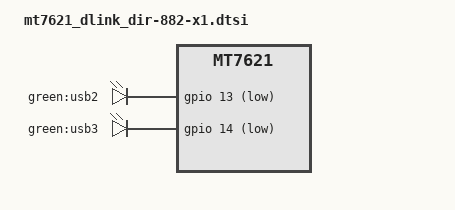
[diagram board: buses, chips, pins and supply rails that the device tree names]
// SPDX-License-Identifier: GPL-2.0-or-later OR MIT

&leds {
	usb2 {
		label = "green:usb2";
		gpios = <&gpio 13 GPIO_ACTIVE_LOW>;
		trigger-sources = <&ehci_port2>;
		linux,default-trigger = "usbport";
	};

	usb3 {
		label = "green:usb3";
		gpios = <&gpio 14 GPIO_ACTIVE_LOW>;
		trigger-sources = <&xhci_ehci_port1>;
		linux,default-trigger = "usbport";
	};
};
